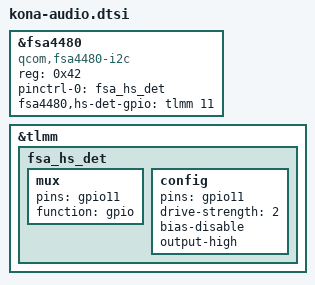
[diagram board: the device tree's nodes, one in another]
#include "msm-audio-lpass.dtsi"

&fsa4480 {
	compatible = "qcom,fsa4480-i2c";
	reg = <0x42>;
	pinctrl-names = "default";
	pinctrl-0 = <&fsa_hs_det>;
	fsa4480,hs-det-gpio = <&tlmm 11 0x00>;
};

&tlmm {
	fsa_hs_det: fsa_hs_det  {
		mux {
			pins = "gpio11";
			function = "gpio";
		};

		config {
			pins = "gpio11";
			drive-strength = <2>;
			bias-disable;
			output-high;
		};
	};
};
